# nrf5340 register map
Vendor: Nordic Semiconductor; Series: nrf53; File version: 1
CPU: CM33 r0p2, little endian, MPU, FPU, 3 interrupt priority bits
Registers are 32-bit, read-write, reset 0x0 unless marked. A register's access mark holds for its fields unless they carry their own. Offsets are from the block's base; [hi:lo] are bit positions; lines under a group give offsets from that group; {n}, {i} and the like mark numbered series; 'fields as' and 'values as' point back to an identical list.

## PCGCMASTER_CM4SS_S — PCGC Master 0
Base 0x50002000
Same registers: PCGCMASTER_APPMAIN_S 0x50100000, PCGCMASTER_APPMCU_S 0x50101000, PCGCMASTER_PERMCU_S 0x50201000, PCGCMASTER_PERMAIN_S 0x50202000, PCGCMASTER_TIMERS_S 0x50203000, PCGCMASTER_PAC_S 0x50300000
{0xE0+4i} SETPWRCONTHESHOLDBASE[{i}] (i=0..2) ro — Description collection: Set power consumption threshold base for power source / regulator n
  [3:0] SETPWRCONTHESHOLDBASE
{0x100+4i} SETPOWERCONSUMPTIONBASE[{i}] (i=0..1) ro — Description collection: Set power consumption base for power/clock pair n
  [3:0] POWERREQUIREMENT
0xC00 UNLOCKBACKDOORS ro
  [15:0] UNLOCKBACKDOORS — Write: 0x00009375 to lock/unlock backdoors Read: 0x00000001 if backdoors is enabled Read: 0x00000000 if backdoors is disabled
0xC04 ENABLEPOWERREGFORCE ro
  [2:0] ENABLEPOWERREGFORCE
0xC08 POWERREGFORCE ro — Force reg
  [2:0] POWERREGFORCEREG
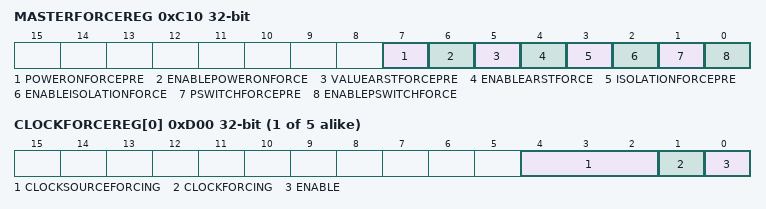
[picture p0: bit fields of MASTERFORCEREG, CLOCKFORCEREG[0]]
0xC10 MASTERFORCEREG ro — Force reg
  [7] POWERONFORCEPRE, [6] ENABLEPOWERONFORCE, [5] VALUEARSTFORCEPRE, [4] ENABLEARSTFORCE, [3] ISOLATIONFORCEPRE, [2] ENABLEISOLATIONFORCE, [1] PSWITCHFORCEPRE, [0] ENABLEPSWITCHFORCE
{0xD00+4i} CLOCKFORCEREG[{i}] (i=0..4) ro — Description collection: Force clock n
  [4:2] CLOCKSOURCEFORCING
  [1] CLOCKFORCING
  [0] ENABLE — Enable clock forcing

## GPIOCONFIG_S — PCGCSlave 0
Base 0x500C0000
Same registers: PCGCSLAVE0_S 0x50102000, INFOCONF_S 0x50104000, PPIMATRIX_MCU_S 0x50105000, WAKEUPPDTIMERS_S 0x50106000, POWERSWITCH_SLAVE_S 0x50107000, PCGCSLAVE_RAMBISTHUB_S 0x50108000, PCGCSLAVE_AMLI_S 0x50109000, PCGCSLAVE_RESETHANDLER_S 0x5010A000, PCGCSLAVE_APPMAIN_S 0x5010B000, APBWUP_TIMER_S 0x50200000, PPIMATRIX_TIMERS_S 0x50204000, PPIMATRIX_PERIPHERALS_S 0x50205000, PPIMATRIX_IPC_S 0x50206000, APBWUP_IPC_S 0x50207000
0x78 TRIGZEROPENALTY ro — Trigger zero penalty
  [0] TRIGGER
    1=Enable (Trigger zero penalty)
0x7C TRIGFULLPENALTY ro — Trigger full penalty
  [0] TRIGGER
    1=Enable (Trigger full penalty)
{0xC00+4i} PENALTY[{i}] (i=0..1) ro — Description collection: Penalty level for power/clock pair n
  [7:0] PENALTY — Penalty level
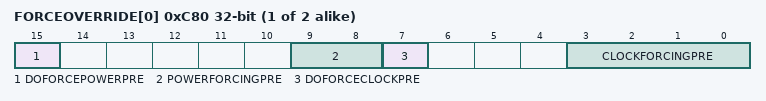
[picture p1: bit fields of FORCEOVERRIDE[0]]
{0xC80+4i} FORCEOVERRIDE[{i}] (i=0..1) ro — Description collection: Force override of power/clock pair n
  [15] DOFORCEPOWERPRE, [9:8] POWERFORCINGPRE, [7] DOFORCECLOCKPRE, [3:0] CLOCKFORCINGPRE

## TAD_S — Trace and debug control
Base 0xE0080000
0x00 FORCEON — Force on debug domain
  [0] FORCEON
    0=DISABLED (Disable force-on of debug domain); 1=ENABLED (Enable force-on of debug domain)
0x500 ENABLE — Enable debug domain and aquire selected GPIOs
  [0] ENABLE
    0=DISABLED (Disable debug domain and release selected GPIOs); 1=ENABLED (Enable debug domain and aquire selected GPIOs)
0x504 PSEL group — Unspecified
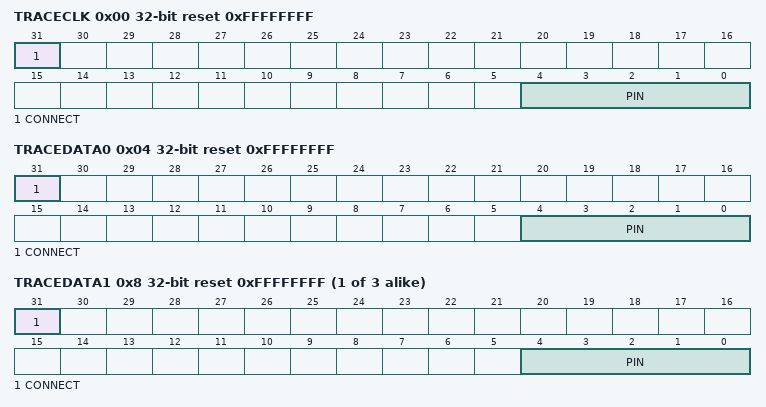
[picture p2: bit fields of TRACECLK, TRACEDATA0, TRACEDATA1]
  0x00 TRACECLK reset 0xFFFFFFFF — Pin number configuration for TRACECLK
    [31] CONNECT — Connection
      1=Disconnected; 0=Connected
    [4:0] PIN — Pin number
  0x04 TRACEDATA0 reset 0xFFFFFFFF — Pin number configuration for TRACEDATA[0] and SWO
    fields as PSEL.TRACECLK
  {0x4+4j} TRACEDATA{j} reset 0xFFFFFFFF (j=1..3) — Pin number configuration for TRACEDATA[{j}]
    fields as PSEL.TRACECLK
0x518 TRACEPORTSPEED — Clocking options for the Trace Port debug interface
  [1:0] TRACEPORTSPEED — Speed of Trace Port clock. Note that the TRACECLK pin will output this clock divided by two.
    0=32 MHz Trace Port clock (TRACECLK = 16 MHz); 1=16 MHz Trace Port clock (TRACECLK = 8 MHz); 2=8 MHz Trace Port clock (TRACECLK = 4 MHz); 3=4 MHz Trace Port clock (TRACECLK = 2 MHz)

## AMLI_NS — AHB Multi-Layer Interface 0
Base 0x40000000
Same registers: AMLI_S 0x50000000
0xE00 RAMPRI group — RAM configurable priority configuration structure
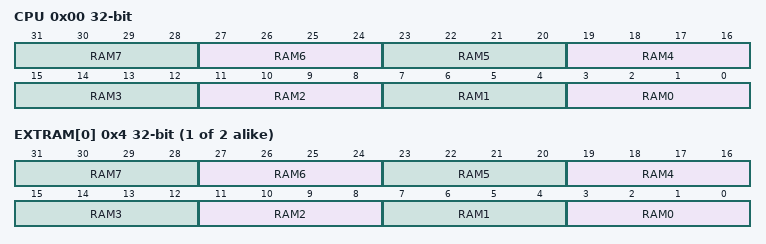
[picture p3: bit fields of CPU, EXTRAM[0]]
  0x00 CPU — AHB bus master priority register for CPU
    [all] fields
      0=Pri0 (Priority 0); 1=Pri1 (Priority 1)
    [4n+3:4n] RAM{n} (n=0..7) — Priority register for RAM AHB slave {n}
  {0x4+4j} EXTRAM[{j}] (j=0..1) — Description collection: AHB bus master priority register for external RAM slave port (EXTRAMs)
    fields as RAMPRI.CPU
